# MB9AF15xR register map
File version: 1.7
CPU: 
Registers are 8-bit, read-write, reset 0x0 unless marked. A register's access mark holds for its fields unless they carry their own. Offsets are from the block's base; [hi:lo] are bit positions; {n}, {i} and the like mark numbered series; 'fields as' and 'values as' point back to an identical list.

## SWWDT — Software Watchdog Timer
Base 0x40012000
0x00 WDOGLOAD 32-bit reset 0xFFFFFFFF — Software Watchdog Timer Load Register
0x04 WDOGVALUE 32-bit ro reset 0xFFFFFFFF — Software Watchdog Timer Value Register
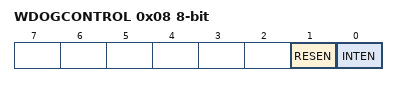
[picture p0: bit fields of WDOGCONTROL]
0x08 WDOGCONTROL — Software Watchdog Timer Control Register
  [1] RESEN — Reset enable bit of the software watchdog
  [0] INTEN — Interrupt and counter enable bit of the software watchdog
0x0C WDOGINTCLR 32-bit reset 0xFFFFFFFF — Software Watchdog Timer Clear Register
0x10 WDOGRIS ro — Software Watchdog Timer Interrupt Status Register
  [0] RIS — Software watchdog interrupt status bit
0xC00 WDOGLOCK 32-bit — Software Watchdog Timer Lock Register

## HWWDT — Hardware Watchdog Timer
Base 0x40011000
0x00 WDG_LDR 32-bit reset 0xFFFF — Hardware Watchdog Timer Load Register
0x04 WDG_VLR 32-bit ro — Hardware Watchdog Timer Value Register
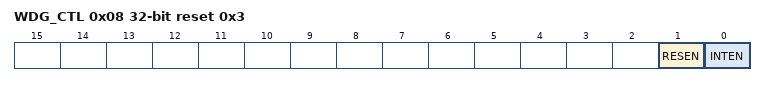
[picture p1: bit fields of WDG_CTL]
0x08 WDG_CTL 32-bit reset 0x3 — Hardware Watchdog Timer Control Register
  [1] RESEN — Hardware watchdog reset enable bit
  [0] INTEN — Hardware watchdog interrupt and counter enable bit
0x0C WDG_ICL reset 0xFF (reset mask 0x0) — Hardware Watchdog Timer Clear Register
0x10 WDG_RIS 1-bit ro reset 0xFF (reset mask 0x0) — Hardware Watchdog Timer Interrupt Status Register
  [0] RIS — Hardware watchdog interrupt status bit
0xC00 WDG_LCK 32-bit reset 0x1 — Hardware Watchdog Timer Lock Register

## DTIM — Dual Timer
Base 0x40015000
0x00 TIMER1LOAD 32-bit (DualTimer1 view) — Load Register
0x04 TIMER1VALUE 32-bit ro reset 0xFFFFFFFF — Value Register
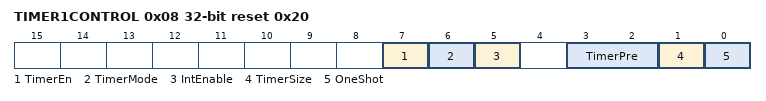
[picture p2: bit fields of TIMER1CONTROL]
0x08 TIMER1CONTROL 32-bit reset 0x20 — Control Register
  [7] TimerEn — Enable bit
  [6] TimerMode — Mode bit
  [5] IntEnable — Interrupt enable bit
  [3:2] TimerPre — Prescale bits
  [1] TimerSize — Counter size bit
  [0] OneShot — One-shot mode bit
0x0C TIMER1INTCLR 32-bit wo reset not defined — Interrupt Clear Register
0x10 TIMER1RIS 32-bit ro — Interrupt Status Register
  [0] TIMER1RIS — Interrupt Status Register bit
0x14 TIMER1MIS 32-bit ro — Masked Interrupt Status Register
  [0] TIMER1MIS — Masked Interrupt Status bit
0x18 TIMER1BGLOAD 32-bit — Background Load Register
0x20 TIMER2LOAD 32-bit reset not defined — Load Register
0x24 TIMER2VALUE 32-bit reset not defined — Value Register
0x28 TIMER2CONTROL 32-bit reset not defined — Control Register
0x2C TIMER2INTCLR 32-bit reset not defined — Interrupt Clear Register
0x30 TIMER2RIS 32-bit reset not defined — Interrupt Status Register
0x34 TIMER2MIS 32-bit reset not defined — Masked Interrupt Status Register
0x38 TIMER2BGLOAD 32-bit reset not defined — Background Load Register

## BTIOSEL03 — Base Timer I/O Select
Base 0x40025100
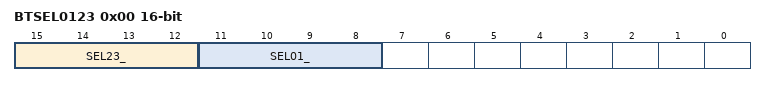
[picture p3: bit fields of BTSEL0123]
0x00 BTSEL0123 16-bit — I/O Select Register
  [15:12] SEL23_ — I/O select bits for Ch.2/Ch.3
  [11:8] SEL01_ — I/O select bits for Ch.0/Ch.1

## BTIOSEL47 — Base Timer I/O Select
Base 0x40025300
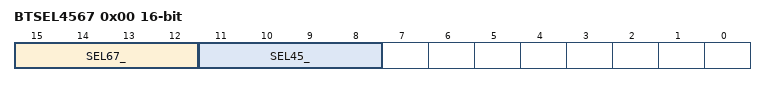
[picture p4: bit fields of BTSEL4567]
0x00 BTSEL4567 16-bit — I/O Select Register
  [15:12] SEL67_ — I/O select bits for Ch.6/Ch.7
  [11:8] SEL45_ — I/O select bits for Ch.4/Ch.5

## BTIOSEL8B — Base Timer I/O Select
Base 0x40025500
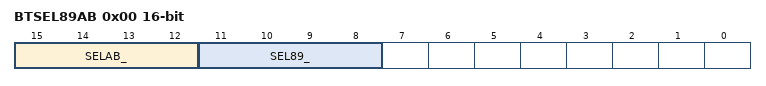
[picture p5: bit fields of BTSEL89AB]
0x00 BTSEL89AB 16-bit — I/O Select Register
  [15:12] SELAB_ — I/O select bits for Ch.A/Ch.B
  [11:8] SEL89_ — I/O select bits for Ch.8/Ch.9

## BTIOSELCF — Base Timer I/O Select
Base 0x40025700
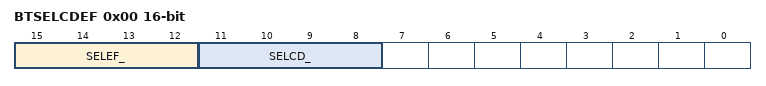
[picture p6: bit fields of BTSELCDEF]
0x00 BTSELCDEF 16-bit — I/O Select Register
  [15:12] SELEF_ — I/O select bits for Ch.E/Ch.F
  [11:8] SELCD_ — I/O select bits for Ch.C/Ch.D

## SBSSR — Software-based Simultaneous Startup Register
Base 0x40025F00
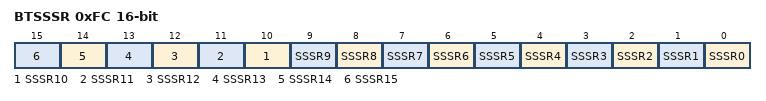
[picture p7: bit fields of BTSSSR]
0xFC BTSSSR 16-bit wo reset not defined — Software-based Simultaneous Startup Register
  [n] SSSR{n} (n=0..15) — Bit{n} of BTSSSR

## BT0 — Base Timer 0
Base 0x40025000
Same registers: BT1 0x40025040, BT2 0x40025080, BT3 0x400250C0, BT4 0x40025200, BT5 0x40025240, BT6 0x40025280, BT7 0x400252C0, BT8 0x40025400, BT9 0x40025440, BT10 0x40025480, BT11 0x400254C0, BT12 0x40025600, BT13 0x40025640, BT14 0x40025680, BT15 0x400256C0
0x00 PWM_PCSR 16-bit reset not defined (PWM view) — PWM Cycle Set Register
0x00 PPG_PRLL 16-bit reset not defined (PPG view) — LOW Width Reload Register
0x00 RT_PCSR 16-bit reset not defined (RT view) — PWM Cycle Set Register
0x04 PWM_PDUT 16-bit reset not defined (PWM view) — PWM Duty Set Register
0x04 PPG_PRLH 16-bit reset not defined (PPG view) — HIGH Width Reload Register
0x04 PWC_DTBF 16-bit ro (PWC view) — Data Buffer Register
0x08 PWM_TMR 16-bit ro (PWM view) — Timer Register
0x08 PPG_TMR 16-bit ro (PPG view) — Timer Register
0x08 RT_TMR 16-bit ro reset not defined (RT view) — Timer Register
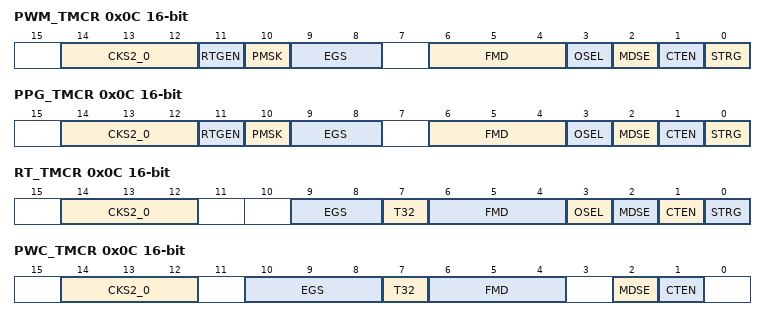
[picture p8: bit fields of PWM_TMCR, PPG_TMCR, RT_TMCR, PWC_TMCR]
0x0C PWM_TMCR 16-bit (PWM view) — Timer Control Register
  [14:12] CKS2_0 — Count clock selection bit
  [11] RTGEN — Restart enable bit
  [10] PMSK — Pulse output mask bit
  [9:8] EGS — Trigger input edge selection bits
  [6:4] FMD — Timer function selection bits
  [3] OSEL — Output polarity specification bit
  [2] MDSE — Mode selection bit
  [1] CTEN — Count operation enable bit
  [0] STRG — Software trigger bit
0x0C PPG_TMCR 16-bit (PPG view) — Timer Control Register
  fields as PWM_TMCR
0x0C RT_TMCR 16-bit (RT view) — Timer Control Register
  [14:12] CKS2_0 — Count clock selection bit
  [9:8] EGS — Trigger input edge selection bits
  [7] T32 — 32-bit timer selection bit
  [6:4] FMD — Timer function selection bits
  [3] OSEL — Output polarity specification bit
  [2] MDSE — Mode selection bit
  [1] CTEN — Timer enable bit
  [0] STRG — Software trigger bit
0x0C PWC_TMCR 16-bit (PWC view) — Timer Control Register
  [14:12] CKS2_0 — Count clock selection bit
  [10:8] EGS — Measurement edge selection bits
  [7] T32 — 32-bit timer selection bit
  [6:4] FMD — Timer function selection bits
  [2] MDSE — Mode selection bit
  [1] CTEN — Timer enable bit
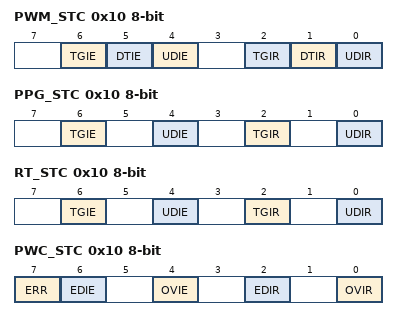
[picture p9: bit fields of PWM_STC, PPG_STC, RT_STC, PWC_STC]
0x10 PWM_STC (PWM view) — Status Control Register
  [6] TGIE — Trigger interrupt request enable bit
  [5] DTIE — Duty match interrupt request enable bit
  [4] UDIE — Underflow interrupt request enable bit
  [2] TGIR — Trigger interrupt request bit
  [1] DTIR — Duty match interrupt request bit
  [0] UDIR — Underflow interrupt request bit
0x10 PPG_STC (PPG view) — Status Control Register
  [6] TGIE — Trigger interrupt request enable bit
  [4] UDIE — Underflow interrupt request enable bit
  [2] TGIR — Trigger interrupt request bit
  [0] UDIR — Underflow interrupt request bit
0x10 RT_STC (RT view) — Status Control Register
  fields as PPG_STC
0x10 PWC_STC (PWC view) — Status Control Register
  [7] ERR ro — Error flag bit
  [6] EDIE — Measurement completion interrupt request enable bit
  [4] OVIE — Overflow interrupt request enable bit
  [2] EDIR ro — Measurement completion interrupt request bit
  [0] OVIR — Overflow interrupt request bit
0x11 PWM_TMCR2 (PWM view) — Timer Control Register 2
  [0] CKS3 — Count clock selection bit
0x11 PPG_TMCR2 (reset mask 0x1) (PPG view) — Timer Control Register 2
  [1] CKS3 — Count clock selection bit
0x11 RT_TMCR2 (RT view) — Timer Control Register 2
  [0] CKS3 — Count clock selection bit
0x11 PWC_TMCR2 (PWC view) — Timer Control Register 2
  [0] CKS3 — Count clock selection bit
